# Montana register map
Vendor: ONSemiconductor; Series: Montana Series; File version: 1.0
CPU: CM33 r0p4, little endian, MPU, FPU, 3 interrupt priority bits
Registers are 32-bit, read-write, reset 0x0 unless marked. A register's access mark holds for its fields unless they carry their own. Offsets are from the block's base; [hi:lo] are bit positions; {n}, {i} and the like mark numbered series.

## ICB — Implementation Control Block
Base 0xE000E004
0x00 ICB_ICTR ro reset 0x1 — Interrupt Controller Type Register
  [3:0] INTLINESNUM — Number of interrupt inputs in steps of 32
    1=NVIC_INTLINESNUM_33_64

## SysTick — SysTick Timer
Base 0xE000E010
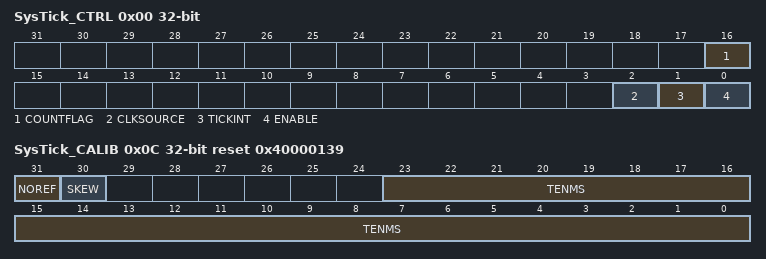
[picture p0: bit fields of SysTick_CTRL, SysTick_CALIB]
0x00 SysTick_CTRL — SysTick Control and Status Register
  [16] COUNTFLAG ro — Reads as 1 if SYSTICK counter has reached 0 since the last time the timer has reached 0. Clears to 0 on read.
    0=SYSTICK_COUNTFLAG_NOT_ZERO (SYSTICK counter has not reached zero since last read); 1=SYSTICK_COUNTFLAG_ZERO (SYSTICK counter has reached zero since last read)
  [2] CLKSOURCE — SYSTICK timer clock source
    0=SYSTICK_CLKSOURCE_EXTREF_CLK (Use external reference clock (STCLK)); 1=SYSTICK_CLKSOURCE_CORE_CLK (Use the core clock)
  [1] TICKINT — SYSTICK timer interrupt enable
    0=SYSTICK_TICKINT_DISABLE (Disable interrupt generation when SYSTICK timer reaches 0); 1=SYSTICK_TICKINT_ENABLE (Enable interrupt generation when SYSTICK timer reaches 0)
  [0] ENABLE — SYSTICK timer enable
    0=SYSTICK_DISABLE (Disable SYSTICK timer); 1=SYSTICK_ENABLE (Enable SYSTICK Timer)
0x04 SysTick_LOAD — SysTick Reload Value Register
  [23:0] RELOAD — Counter reload value for the SYSTICK timer when it reaches 0
0x08 SysTick_VAL — SysTick Current Value Register
  [23:0] CURRENT — Current value of the SYSTICK counter value. Write to clear counter.
0x0C SysTick_CALIB ro reset 0x40000139 — SysTick Calibration Register
  [31] NOREF — Indicates if a reference clock is available
    1=SYSTICK_NOREF (No external reference clock available); 0=SYSTICK_REF (External reference clock available)
  [30] SKEW — Indicates if calibration value is exactly 10 ms or not
    1=SYSTICK_SKEW (Calibration value is not exactly 10 ms); 0=SYSTICK_NOSKEW (Calibration value is exactly 10 ms)
  [23:0] TENMS — SYSTICK counter calibration value for 10 ms. A value of 0 means the calibration value is not available

## MPU — Memory Protection Unit
Base 0xE000ED90
0x00 MPU_TYPE ro reset 0x400 — Indicates how many regions the MPU for the selected security state supports
  [15:8] NBR_OF_REGION — Number of regions
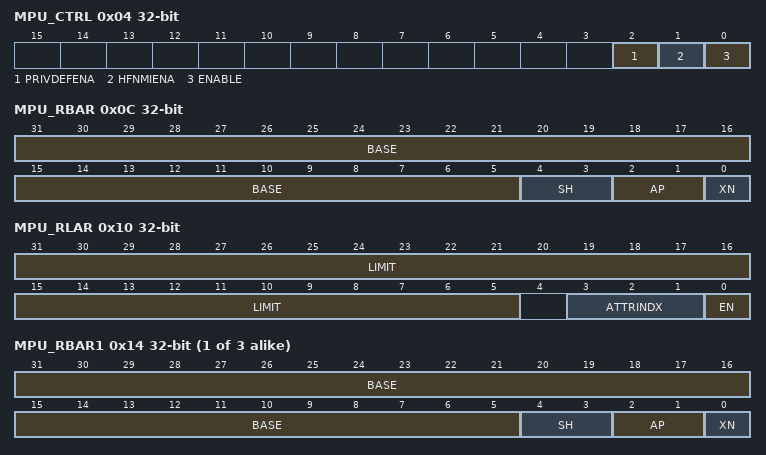
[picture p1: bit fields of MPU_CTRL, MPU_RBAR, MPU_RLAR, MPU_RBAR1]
0x04 MPU_CTRL — MPU control register
  [2] PRIVDEFENA — Privileged default enable
    0=DEFAULT_MEM_MAP_DISABLED (Disables use of the default memory map. Any memory access to a location that is not covered by any enabled region causes a fault); 1=DEFAULT_MEM_MAP_ENABLED (Enables use of the default memory map as a background region for privileged software accesses)
  [1] HFNMIENA — Hard fault and NMI enable
    0=MPU_DISABLED_FOR_HF_NMI (MPU is disabled during HardFault and NMI handlers, regardless of the value of the ENABLE bit); 1=MPU_ENABLED_FOR_HF_NMI (The MPU is enabled during HardFault and NMI handlers)
  [0] ENABLE — Enable the MPU
    0=MPU_DISABLED (MPU is disabled); 1=MPU_ENABLED (MPU is enabled)
0x08 MPU_RNR ro — MPU Region Number Register
  [7:0] REGION — Region number
0x0C MPU_RBAR — MPU Region Base Address Register
  [31:5] BASE — Base address
  [4:3] SH — Shareability
    0=NON_SHAREABLE; 2=OUTER_SHAREABLE; 3=INNER_SHAREABLE
  [2:1] AP — Access permissions
    0=RW_PRIVILEGED_CODE_ONLY (Read/write by privileged code only); 1=RW_PRIVILEGED_LEVEL (Read/write by any privilege level); 2=R_PRIVILEGED_CODE_ONLY (Read-only by privileged code only); 3=R_PRIVILEGED_LEVEL (Read-only by any privilege level)
  [0] XN — Execute never
    0=EXEC_PERMITED (Execution only permitted if read permitted); 1=EXEC_NOT_PERMITTED (Execution not permitted)
0x10 MPU_RLAR — MPU Region Limit Address Register
  [31:5] LIMIT — Limit address
  [3:1] ATTRINDX — Attribute index
  [0] EN — Region enable
    0=REGION_DISABLED; 1=REGION_ENABLED
{0xC+8i} MPU_RBAR{i} (i=1..3) — MPU Region {i} Base Address Register
  [31:5] BASE — Base address
  [4:3] SH — Shareability
  [2:1] AP — Access permissions
  [0] XN — Execute never
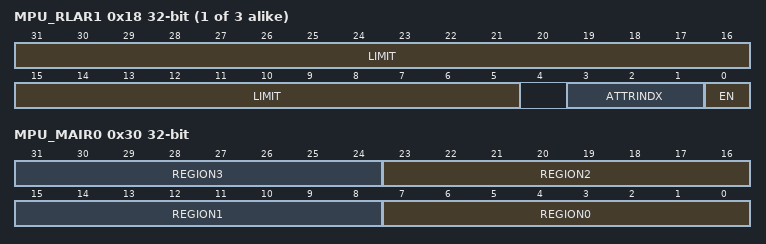
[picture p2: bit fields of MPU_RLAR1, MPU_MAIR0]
{0x10+8i} MPU_RLAR{i} (i=1..3) — MPU Region {i} Limit Address Register
  [31:5] LIMIT — Limit address
  [3:1] ATTRINDX — Attribute index
  [0] EN — Region enable
0x30 MPU_MAIR0 — MPU Memoryattribute Indirection Register 0
  [8n+7:8n] REGION{n} (n=0..3) — Memory attribute encoding for MPU regions {n}
